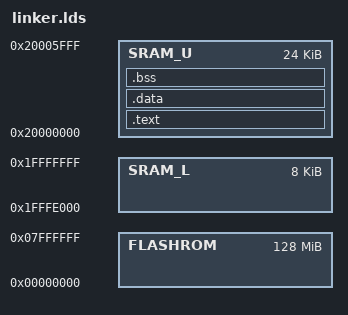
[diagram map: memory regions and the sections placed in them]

ENTRY(_start)

MEMORY
{
        FLASHROM : ORIGIN = 0,          LENGTH = 0x08000000     /* 256 kB */
        SRAM_L   : ORIGIN = 0x1FFFE000, LENGTH = 0x00002000     /* 8 kB */
        SRAM_U   : ORIGIN = 0x20000000, LENGTH = 0x00006000     /* 24 kB */
}

SECTIONS
{
        /**********************************************************************
         *                                                                    *
         **********************************************************************/
        .text :
        {
                _stext = .;
                *(.startup)
                *(.text)
                *(.text.*)
                *(.rodata)
                *(.rodata.*)
                . = ALIGN(0x10);
                _etext = .;
        } > SRAM_U
        /**********************************************************************
         *                                                                    *
         **********************************************************************/
        .data :
        {
                _sdata = .;
                *(.data)
                *(.data.*)
                . = ALIGN(0x10);
                _edata = .;
        } > SRAM_U
        /**********************************************************************
         *                                                                    *
         **********************************************************************/
        .bss ADDR(.data) + SIZEOF(.data) (NOLOAD) :
        {
                _sbss = .;
                *(.bss)
                *(.bss.*)
                *(COMMON)
                . = ALIGN(0x10);
                _ebss = .;
        } > SRAM_U
        /**********************************************************************
         *                                                                    *
         **********************************************************************/
        .debug_info     0 : { *(.debug_info) }
        .debug_abbrev   0 : { *(.debug_abbrev) }
        .debug_aranges  0 : { *(.debug_aranges) }
        .debug_frame    0 : { *(.debug_frame) }
        .debug_line     0 : { *(.debug_line) }
        .debug_line_str 0 : { *(.debug_line_str) }
        .debug_loclists 0 : { *(.debug_loclists) }
        .debug_macro    0 : { *(.debug_macro) }
        .debug_names    0 : { *(.debug_names) }
        .debug_rnglists 0 : { *(.debug_rnglists) }
        .debug_str      0 : { *(.debug_str) }
        /**********************************************************************
         *                                                                    *
         **********************************************************************/
        /DISCARD/ :
        {
                *(*)
        }
}

